# WKUP_CTRL_MMR0_CFG0 register map
Vendor: Texas Instruments
Registers are 32-bit, read-write, reset 0x0 unless marked. A register's access mark holds for its fields unless they carry their own. Offsets are as the file gives them; [hi:lo] are bit positions; lines under a group give offsets from that group; {n}, {i} and the like mark numbered series.

## WKUP_CTRL_MMR0_CFG0 (part 7 of 11)
0x1A0A0 CFG0_TEMP_DIODE_TRIM_PROXY
  [13:0] TEMP_DIODE_TRIM_TRIM_PROXY — Sets the diode non-ideality factor (n), starting from 100th place decimal and going down
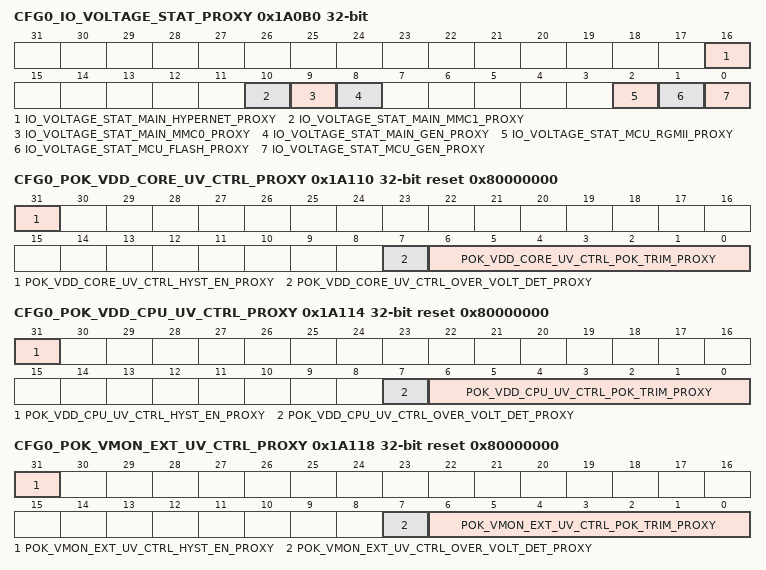
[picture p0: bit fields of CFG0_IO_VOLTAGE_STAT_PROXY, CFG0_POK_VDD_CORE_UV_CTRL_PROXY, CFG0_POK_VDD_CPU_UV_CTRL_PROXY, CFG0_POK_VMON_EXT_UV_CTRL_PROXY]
0x1A0B0 CFG0_IO_VOLTAGE_STAT_PROXY ro
  [16] IO_VOLTAGE_STAT_MAIN_HYPERNET_PROXY — Indicates the voltage for the HYPERNET I/O group 0 - I/O group is set for 1.8V 1 - I/O group is set for 3.3V
  [10] IO_VOLTAGE_STAT_MAIN_MMC1_PROXY — Indicates the voltage for the MMC1 I/O group 0 - I/O group is set for 1.8V 1 - I/O group is set for 3.3V
  [9] IO_VOLTAGE_STAT_MAIN_MMC0_PROXY — Indicates the voltage for the MMC0 I/O group 0 - I/O group is set for 1.8V 1 - I/O group is set for 3.3V
  [8] IO_VOLTAGE_STAT_MAIN_GEN_PROXY — Indicates the voltage for the General I/O group 0 - I/O group is set for 1.8V 1 - I/O group is set for 3.3V
  [2] IO_VOLTAGE_STAT_MCU_RGMII_PROXY — Indicates the voltage for the MCU CPSW2G RGMII I/O group 0 - I/O group is set for 1.8V 1 - I/O group is set for 3.3V
  [1] IO_VOLTAGE_STAT_MCU_FLASH_PROXY — Indicates the voltage for the MCU Flash I/O group 0 - I/O group is set for 1.8V 1 - I/O group is set for 3.3V
  [0] IO_VOLTAGE_STAT_MCU_GEN_PROXY — Indicates the voltage for the MCU General I/O group 0 - I/O group is set for 1.8V 1 - I/O group is set for 3.3V
0x1A104 CFG0_MAIN_POR_TO_CTRL_PROXY
  [2:0] MAIN_POR_TO_CTRL_TIMEOUT_PER_PROXY — MAIN PORz hardware timeout period. During normal operation, the assertion of a MAIN Domain PORz generates a reset request interrupt to the DMSC. The DMSC then performs steps to properly isolate the MAIN Domain before the actual reset is performed. A hardware timeout mechanism is provided to ensure that the PORz gets propagated to the MAIN Domain in the event that a error prevents the DMSC from completing the reset isolation. Field values (others are reserved): 3'b000 - Immediate 3'b001 - 100 microsec 3'b010 - 200 microsec 3'b011 - 300 microsec 3'b100 - 400 microsec 3'b101 - 500 microsec
0x1A110 CFG0_POK_VDD_CORE_UV_CTRL_PROXY reset 0x80000000
  [31] POK_VDD_CORE_UV_CTRL_HYST_EN_PROXY — Enable POK hysteresis
  [7] POK_VDD_CORE_UV_CTRL_OVER_VOLT_DET_PROXY — Over / under voltage detection mode 0 - Under voltage detection 1 - Over voltage detection
  [6:0] POK_VDD_CORE_UV_CTRL_POK_TRIM_PROXY — POK trim bits. These bits are used to trim the comparator threshold voltage. See POK spec and efuse spec for details
0x1A114 CFG0_POK_VDD_CPU_UV_CTRL_PROXY reset 0x80000000
  [31] POK_VDD_CPU_UV_CTRL_HYST_EN_PROXY — Enable POK hysteresis
  [7] POK_VDD_CPU_UV_CTRL_OVER_VOLT_DET_PROXY — Over / under voltage detection mode 0 - Under voltage detection 1 - Over voltage detection
  [6:0] POK_VDD_CPU_UV_CTRL_POK_TRIM_PROXY — POK trim bits. These bits are used to trim the comparator threshold voltage. See POK spec and efuse spec for details
0x1A118 CFG0_POK_VMON_EXT_UV_CTRL_PROXY reset 0x80000000
  [31] POK_VMON_EXT_UV_CTRL_HYST_EN_PROXY — Enable POK hysteresis
  [7] POK_VMON_EXT_UV_CTRL_OVER_VOLT_DET_PROXY — Over / under voltage detection mode 0 - Under voltage detection 1 - Over voltage detection
  [6:0] POK_VMON_EXT_UV_CTRL_POK_TRIM_PROXY — POK trim bits. These bits are used to trim the comparator threshold voltage. See POK spec and efuse spec for details
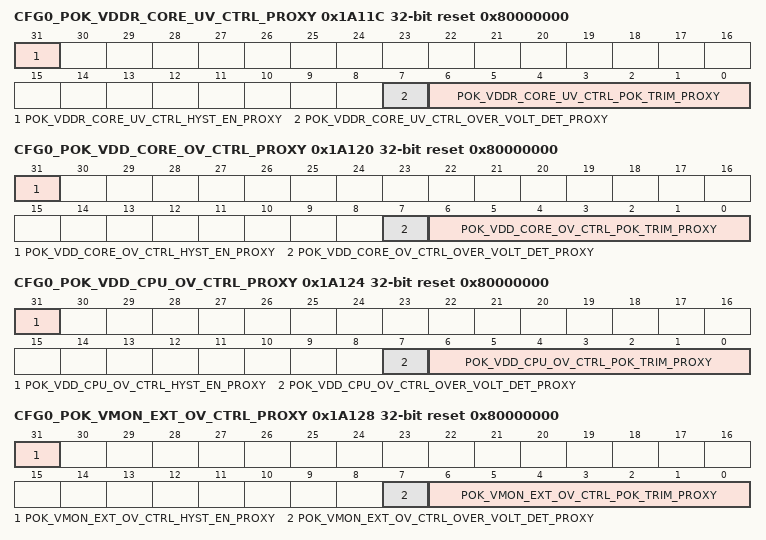
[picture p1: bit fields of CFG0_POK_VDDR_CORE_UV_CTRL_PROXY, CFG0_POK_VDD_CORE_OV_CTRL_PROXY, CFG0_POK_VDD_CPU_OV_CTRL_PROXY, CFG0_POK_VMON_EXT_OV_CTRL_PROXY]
0x1A11C CFG0_POK_VDDR_CORE_UV_CTRL_PROXY reset 0x80000000
  [31] POK_VDDR_CORE_UV_CTRL_HYST_EN_PROXY — Enable POK hysteresis
  [7] POK_VDDR_CORE_UV_CTRL_OVER_VOLT_DET_PROXY — Over / under voltage detection mode 0 - Under voltage detection 1 - Over voltage detection
  [6:0] POK_VDDR_CORE_UV_CTRL_POK_TRIM_PROXY — POK trim bits. These bits are used to trim the comparator threshold voltage. See POK spec and efuse spec for details
0x1A120 CFG0_POK_VDD_CORE_OV_CTRL_PROXY reset 0x80000000
  [31] POK_VDD_CORE_OV_CTRL_HYST_EN_PROXY — Enable POK hysteresis
  [7] POK_VDD_CORE_OV_CTRL_OVER_VOLT_DET_PROXY — Over / under voltage detection mode 0 - Under voltage detection 1 - Over voltage detection
  [6:0] POK_VDD_CORE_OV_CTRL_POK_TRIM_PROXY — POK trim bits. These bits are used to trim the comparator threshold voltage. See POK spec and efuse spec for details
0x1A124 CFG0_POK_VDD_CPU_OV_CTRL_PROXY reset 0x80000000
  [31] POK_VDD_CPU_OV_CTRL_HYST_EN_PROXY — Enable POK hysteresis
  [7] POK_VDD_CPU_OV_CTRL_OVER_VOLT_DET_PROXY — Over / under voltage detection mode 0 - Under voltage detection 1 - Over voltage detection
  [6:0] POK_VDD_CPU_OV_CTRL_POK_TRIM_PROXY — POK trim bits. These bits are used to trim the comparator threshold voltage. See POK spec and efuse spec for details
0x1A128 CFG0_POK_VMON_EXT_OV_CTRL_PROXY reset 0x80000000
  [31] POK_VMON_EXT_OV_CTRL_HYST_EN_PROXY — Enable POK hysteresis
  [7] POK_VMON_EXT_OV_CTRL_OVER_VOLT_DET_PROXY — Over / under voltage detection mode 0 - Under voltage detection 1 - Over voltage detection
  [6:0] POK_VMON_EXT_OV_CTRL_POK_TRIM_PROXY — POK trim bits. These bits are used to trim the comparator threshold voltage. See POK spec and efuse spec for details
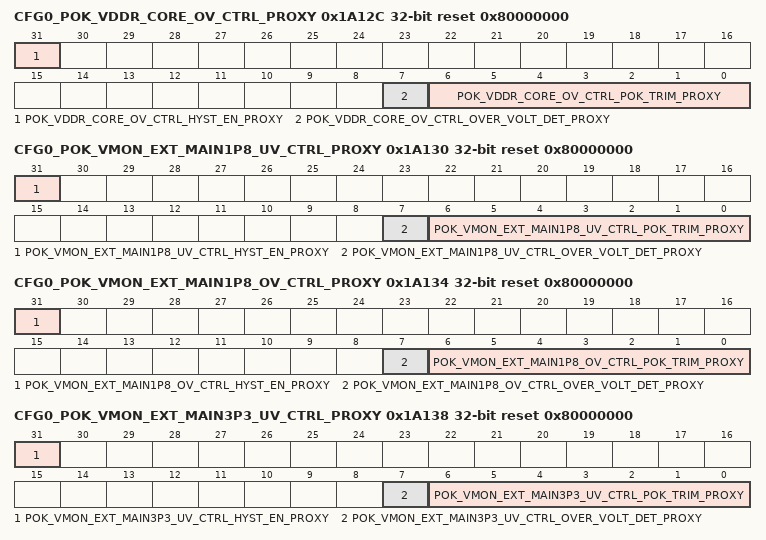
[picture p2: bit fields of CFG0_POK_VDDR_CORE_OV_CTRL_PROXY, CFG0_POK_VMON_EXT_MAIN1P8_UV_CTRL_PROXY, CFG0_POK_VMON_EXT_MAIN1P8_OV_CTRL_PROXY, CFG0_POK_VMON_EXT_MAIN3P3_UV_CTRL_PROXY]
0x1A12C CFG0_POK_VDDR_CORE_OV_CTRL_PROXY reset 0x80000000
  [31] POK_VDDR_CORE_OV_CTRL_HYST_EN_PROXY — Enable POK hysteresis
  [7] POK_VDDR_CORE_OV_CTRL_OVER_VOLT_DET_PROXY — Over / under voltage detection mode 0 - Under voltage detection 1 - Over voltage detection
  [6:0] POK_VDDR_CORE_OV_CTRL_POK_TRIM_PROXY — POK trim bits. These bits are used to trim the comparator threshold voltage. See POK spec and efuse spec for details
0x1A130 CFG0_POK_VMON_EXT_MAIN1P8_UV_CTRL_PROXY reset 0x80000000
  [31] POK_VMON_EXT_MAIN1P8_UV_CTRL_HYST_EN_PROXY — Enable POK hysteresis
  [7] POK_VMON_EXT_MAIN1P8_UV_CTRL_OVER_VOLT_DET_PROXY — Over / under voltage detection mode 0 - Under voltage detection 1 - Over voltage detection
  [6:0] POK_VMON_EXT_MAIN1P8_UV_CTRL_POK_TRIM_PROXY — POK trim bits. These bits are used to trim the comparator threshold voltage. See POK spec and efuse spec for details
0x1A134 CFG0_POK_VMON_EXT_MAIN1P8_OV_CTRL_PROXY reset 0x80000000
  [31] POK_VMON_EXT_MAIN1P8_OV_CTRL_HYST_EN_PROXY — Enable POK hysteresis
  [7] POK_VMON_EXT_MAIN1P8_OV_CTRL_OVER_VOLT_DET_PROXY — Over / under voltage detection mode 0 - Under voltage detection 1 - Over voltage detection
  [6:0] POK_VMON_EXT_MAIN1P8_OV_CTRL_POK_TRIM_PROXY — POK trim bits. These bits are used to trim the comparator threshold voltage. See POK spec and efuse spec for details
0x1A138 CFG0_POK_VMON_EXT_MAIN3P3_UV_CTRL_PROXY reset 0x80000000
  [31] POK_VMON_EXT_MAIN3P3_UV_CTRL_HYST_EN_PROXY — Enable POK hysteresis
  [7] POK_VMON_EXT_MAIN3P3_UV_CTRL_OVER_VOLT_DET_PROXY — Over / under voltage detection mode 0 - Under voltage detection 1 - Over voltage detection
  [6:0] POK_VMON_EXT_MAIN3P3_UV_CTRL_POK_TRIM_PROXY — POK trim bits. These bits are used to trim the comparator threshold voltage. See POK spec and efuse spec for details
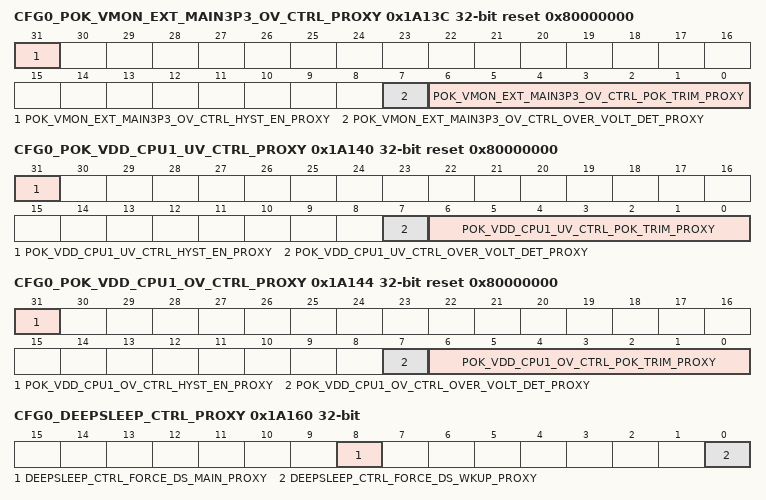
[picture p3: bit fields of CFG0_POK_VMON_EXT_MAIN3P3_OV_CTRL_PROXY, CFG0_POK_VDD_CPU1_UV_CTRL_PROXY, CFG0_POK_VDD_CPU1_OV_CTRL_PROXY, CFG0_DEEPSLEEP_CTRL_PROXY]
0x1A13C CFG0_POK_VMON_EXT_MAIN3P3_OV_CTRL_PROXY reset 0x80000000
  [31] POK_VMON_EXT_MAIN3P3_OV_CTRL_HYST_EN_PROXY — Enable POK hysteresis
  [7] POK_VMON_EXT_MAIN3P3_OV_CTRL_OVER_VOLT_DET_PROXY — Over / under voltage detection mode 0 - Under voltage detection 1 - Over voltage detection
  [6:0] POK_VMON_EXT_MAIN3P3_OV_CTRL_POK_TRIM_PROXY — POK trim bits. These bits are used to trim the comparator threshold voltage. See POK spec and efuse spec for details
0x1A140 CFG0_POK_VDD_CPU1_UV_CTRL_PROXY reset 0x80000000
  [31] POK_VDD_CPU1_UV_CTRL_HYST_EN_PROXY — Enable POK hysteresis
  [7] POK_VDD_CPU1_UV_CTRL_OVER_VOLT_DET_PROXY — Over / under voltage detection mode 0 - Under voltage detection 1 - Over voltage detection
  [6:0] POK_VDD_CPU1_UV_CTRL_POK_TRIM_PROXY — POK trim bits. These bits are used to trim the comparator threshold voltage. See POK spec and efuse spec for details
0x1A144 CFG0_POK_VDD_CPU1_OV_CTRL_PROXY reset 0x80000000
  [31] POK_VDD_CPU1_OV_CTRL_HYST_EN_PROXY — Enable POK hysteresis
  [7] POK_VDD_CPU1_OV_CTRL_OVER_VOLT_DET_PROXY — Over / under voltage detection mode 0 - Under voltage detection 1 - Over voltage detection
  [6:0] POK_VDD_CPU1_OV_CTRL_POK_TRIM_PROXY — POK trim bits. These bits are used to trim the comparator threshold voltage. See POK spec and efuse spec for details
{0x1A150+4i} CFG0_POK_RSV{i}_PROXY access not given (i=0..3)
0x1A160 CFG0_DEEPSLEEP_CTRL_PROXY
  [8] DEEPSLEEP_CTRL_FORCE_DS_MAIN_PROXY — Force all MAIN IOs into deepsleep mode when set
  [0] DEEPSLEEP_CTRL_FORCE_DS_WKUP_PROXY — Force all WKUP IOs into deepsleep mode when set
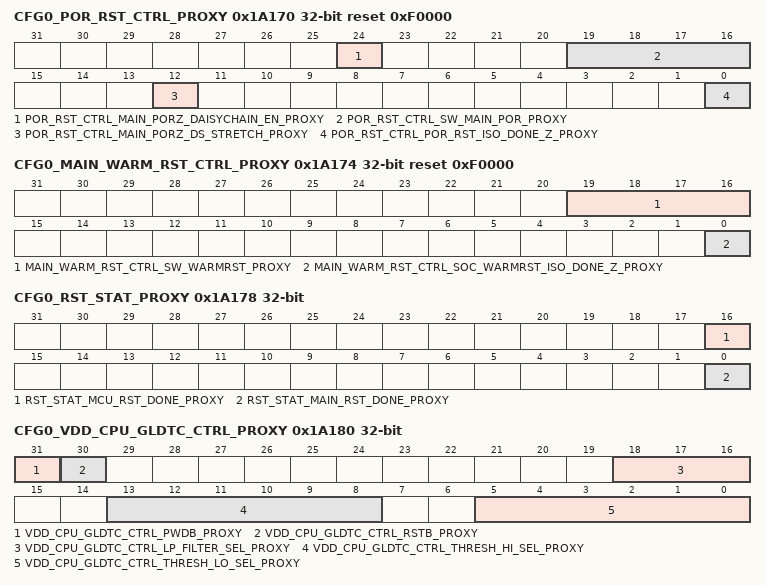
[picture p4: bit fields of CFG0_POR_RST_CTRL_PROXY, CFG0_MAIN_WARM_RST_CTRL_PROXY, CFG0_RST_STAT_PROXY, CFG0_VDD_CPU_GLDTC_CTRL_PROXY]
0x1A170 CFG0_POR_RST_CTRL_PROXY reset 0xF0000
  [24] POR_RST_CTRL_MAIN_PORZ_DAISYCHAIN_EN_PROXY — MAIN PORz daisy-chain event enable. Determines if MAIN PORz reset events affect daisy-chain wakeup 0 - DeepSleep MAIN PORz event is not part of daisy-chain 1 - DeepSleep MAIN PORz event is combined w/ other daisy chain events.
  [19:16] POR_RST_CTRL_SW_MAIN_POR_PROXY — Main Domain software power-on reset. When set to 4'b0110, a power-on is issued to the MAIN voltage domain. (Bits will reset to 4'b1111 on reset of the Main Domain)
  [12] POR_RST_CTRL_MAIN_PORZ_DS_STRETCH_PROXY — DeepSleep mode MAIN PORz stretch. 0 - No stretching 1 - Stretch the Main PORz event captured during DeepSleep mode
  [0] POR_RST_CTRL_POR_RST_ISO_DONE_Z_PROXY — Reset isolation completion (active low). This bit should be cleared only after reset isolation of the MAIN domain is complete. 0 - POR reset propagates to MAIN domain 1 - POR reset blocked from MAIN domain
0x1A174 CFG0_MAIN_WARM_RST_CTRL_PROXY reset 0xF0000
  [19:16] MAIN_WARM_RST_CTRL_SW_WARMRST_PROXY — Main Domain software warm reset. When set to 4'b0110, a warm reset is issued to the MAIN voltage domain. (Bits will reset to 4'b1111 on reset of the Main Domain)
  [0] MAIN_WARM_RST_CTRL_SOC_WARMRST_ISO_DONE_Z_PROXY — Reset isolation completion (active low). This bit should be cleared only after reset isolation of the MAIN domain is complete. 0 - Warm reset propagates to MAIN domain 1 - Warm reset blocked from MAIN domain
0x1A178 CFG0_RST_STAT_PROXY ro
  [16] RST_STAT_MCU_RST_DONE_PROXY — Indicates MCU domain reset status. 0 - MCU domain is in reset 1 - MCU domain reset is complete
  [0] RST_STAT_MAIN_RST_DONE_PROXY — Indicates MAIN domain Warm reset status. 0 - MAIN domain is in Warm reset 1 - MAIN domain Warm reset is complete
0x1A17C CFG0_MCU_WARM_RST_CTRL_PROXY reset 0xF0000
  [19:16] MCU_WARM_RST_CTRL_SW_WARMRST_PROXY — Chip software warm reset. When set to 4'b0110, a warm reset is issued to the device (all voltage domains). (Bits will reset to 4'b1111 on reset completion.)
0x1A180 CFG0_VDD_CPU_GLDTC_CTRL_PROXY
  [31] VDD_CPU_GLDTC_CTRL_PWDB_PROXY — Power down - active low. 0 - Disable all functions 1 - Enable glitch detectors
  [30] VDD_CPU_GLDTC_CTRL_RSTB_PROXY — Reset - active low. To ensure proper operation, rstb must be not be de-asserted for at least 100 ns after power-up (pwdb de-asserted). Additionally, rstb must be toggled low at least 200 ns after any change in threshold or low-pass filter settings to prevent abnormal trigger events. 0 - Reset glitch detector flags 1 - Glitch detection flags are enabled
  [18:16] VDD_CPU_GLDTC_CTRL_LP_FILTER_SEL_PROXY — Selects the glitch detect low-pass filter bandwidth Field values (others are reserved): 3'b000 - 150 kHz 3'b001 - 125 kHz 3'b010 - 100 kHz 3'b011 - 80 kHz 3'b100 - 60 kHz 3'b101 - 45 kHz 3'b110 - 30 kHz 3'b111 - 15 kHz
  [13:8] VDD_CPU_GLDTC_CTRL_THRESH_HI_SEL_PROXY — Selects the high voltage glitch threshold as a percentage of the monitored voltage Field values (others are reserved): 6'b000000 - 93.5% of VDD 6'b000001 - 94.0% of VDD 6'b000010 - 94.5% of VDD 6'b000011 - 95.0% of VDD 6'b000100 - 95.5% of VDD 6'b000101 - 96.0% of VDD 6'b000110 - 96.5% of VDD 6'b000111 - 97.0% of VDD 6'b001000 - 97.5% of VDD 6'b001001 - 98.0% of VDD 6'b001010 - 98.5% of VDD 6'b001011 - 99.0% of VDD 6'b001100 - 99.5% of VDD 6'b001101 - 100.0% of VDD 6'b001110 - 100.5% of VDD 6'b001111 - 101.0% of VDD 6'b010000 - 101.5% of VDD 6'b010001 - 102.0% of VDD 6'b010010 - 102.5% of VDD 6'b010011 - 103.0% of VDD 6'b010100 - 103.5% of VDD 6'b010101 - 104.0% of VDD 6'b010110 - 104.5% of VDD 6'b010111 - 105.0% of VDD 6'b011000 - 105.5% of VDD 6'b011001 - 106.0% of VDD 6'b011010 - 106.5% of VDD 6'b011011 - 107.0% of VDD 6'b011100 - 107.5% of VDD 6'b011101 - 108.0% of VDD 6'b011110 - 108.5% of VDD 6'b011111 - 109.0% of VDD 6'b100000 - 109.5% of VDD 6'b100001 - 110.0% of VDD 6'b100010 - 111.0% of VDD 6'b100011 - 112.0% of VDD 6'b100100 - 113.0% of VDD 6'b100101 - 114.0% of VDD 6'b100110 - 115.0% of VDD 6'b100111 - 116.0% of VDD 6'b101000 - 117.0% of VDD 6'b101001 - 118.0% of VDD 6'b101010 - 119.0% of VDD 6'b101011 - 120.0% of VDD 6'b101100 - 121.0% of VDD 6'b101101 - 122.0% of VDD 6'b101110 - 123.0% of VDD 6'b101111 - 124.0% of VDD 6'b110000 - 125.0% of VDD 6'b110001 - 126.0% of VDD 6'b110010 - 127.0% of VDD 6'b110011 - 128.0% of VDD 6'b110100 - 129.0% of VDD 6'b110101 - 130.0% of VDD 6'b110110 - 131.0% of VDD 6'b110111 - 132.0% of VDD 6'b111000 - 133.0% of VDD 6'b111001 - 134.0% of VDD 6'b111010 - 135.0% of VDD 6'b111011 - 136.0% of VDD 6'b111100 - 137.0% of VDD 6'b111101 - 138.0% of VDD 6'b111110 - 139.0% of VDD 6'b111111 - 140.0% of VDD
  [5:0] VDD_CPU_GLDTC_CTRL_THRESH_LO_SEL_PROXY — Selects the low voltage glitch threshold as a percentage of the monitored voltage Field values (others are reserved): 6'b000000 - 106.5% of VDD 6'b000001 - 106.0% of VDD 6'b000010 - 105.5% of VDD 6'b000011 - 105.0% of VDD 6'b000100 - 104.5% of VDD 6'b000101 - 104.0% of VDD 6'b000110 - 103.5% of VDD 6'b000111 - 103.0% of VDD 6'b001000 - 102.5% of VDD 6'b001001 - 102.0% of VDD 6'b001010 - 101.5% of VDD 6'b001011 - 101.0% of VDD 6'b001100 - 100.5% of VDD 6'b001101 - 100.0% of VDD 6'b001110 - 99.5% of VDD 6'b001111 - 99.0% of VDD 6'b010000 - 98.5% of VDD 6'b010001 - 98.0% of VDD 6'b010010 - 97.5% of VDD 6'b010011 - 97.0% of VDD 6'b010100 - 96.5% of VDD 6'b010101 - 96.0% of VDD 6'b010110 - 95.5% of VDD 6'b010111 - 95.0% of VDD 6'b011000 - 94.5% of VDD 6'b011001 - 94.0% of VDD 6'b011010 - 93.5% of VDD 6'b011011 - 93.0% of VDD 6'b011100 - 92.5% of VDD 6'b011101 - 92.0% of VDD 6'b011110 - 91.5% of VDD 6'b011111 - 91.0% of VDD 6'b100000 - 90.5% of VDD 6'b100001 - 90.0% of VDD 6'b100010 - 89.0% of VDD 6'b100011 - 88.0% of VDD 6'b100100 - 87.0% of VDD 6'b100101 - 86.0% of VDD 6'b100110 - 85.0% of VDD 6'b100111 - 84.0% of VDD 6'b101000 - 83.0% of VDD 6'b101001 - 82.0% of VDD 6'b101010 - 81.0% of VDD 6'b101011 - 80.0% of VDD 6'b101100 - 79.0% of VDD 6'b101101 - 78.0% of VDD 6'b101110 - 77.0% of VDD 6'b101111 - 76.0% of VDD 6'b110000 - 75.0% of VDD 6'b110001 - 74.0% of VDD 6'b110010 - 73.0% of VDD 6'b110011 - 72.0% of VDD 6'b110100 - 71.0% of VDD 6'b110101 - 70.0% of VDD 6'b110110 - 69.0% of VDD 6'b110111 - 68.0% of VDD 6'b111000 - 67.0% of VDD 6'b111001 - 66.0% of VDD 6'b111010 - 65.0% of VDD 6'b111011 - 64.0% of VDD 6'b111100 - 63.0% of VDD 6'b111101 - 62.0% of VDD 6'b111110 - 61.0% of VDD 6'b111111 - 60.0% of VDD
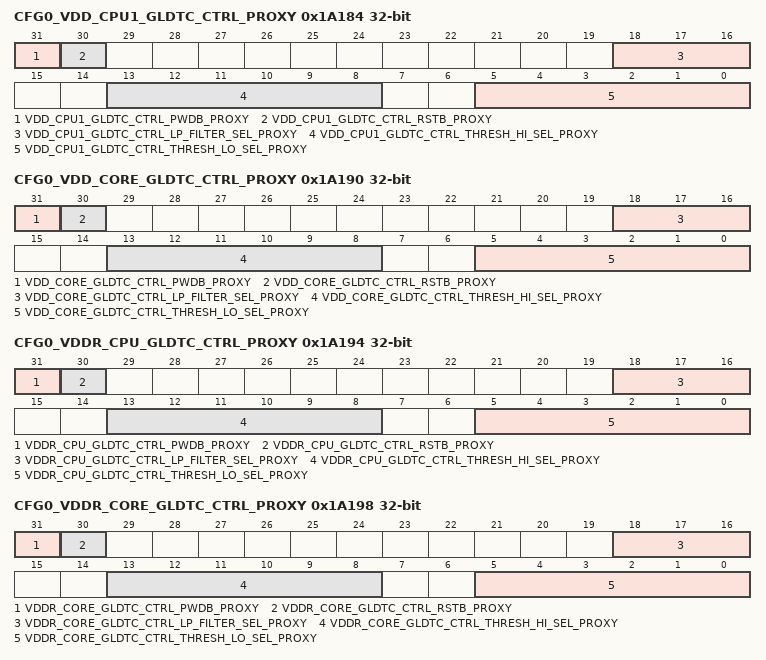
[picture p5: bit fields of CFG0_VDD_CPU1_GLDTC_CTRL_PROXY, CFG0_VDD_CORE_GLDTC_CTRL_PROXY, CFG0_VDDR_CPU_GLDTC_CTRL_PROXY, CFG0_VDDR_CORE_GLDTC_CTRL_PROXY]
0x1A184 CFG0_VDD_CPU1_GLDTC_CTRL_PROXY
  [31] VDD_CPU1_GLDTC_CTRL_PWDB_PROXY — Power down - active low. 0 - Disable all functions 1 - Enable glitch detectors
  [30] VDD_CPU1_GLDTC_CTRL_RSTB_PROXY — Reset - active low. To ensure proper operation, rstb must be not be de-asserted for at least 100 ns after power-up (pwdb de-asserted). Additionally, rstb must be toggled low at least 200 ns after any change in threshold or low-pass filter settings to prevent abnormal trigger events. 0 - Reset glitch detector flags 1 - Glitch detection flags are enabled
  [18:16] VDD_CPU1_GLDTC_CTRL_LP_FILTER_SEL_PROXY — Selects the glitch detect low-pass filter bandwidth Field values (others are reserved): 3'b000 - 150 kHz 3'b001 - 125 kHz 3'b010 - 100 kHz 3'b011 - 80 kHz 3'b100 - 60 kHz 3'b101 - 45 kHz 3'b110 - 30 kHz 3'b111 - 15 kHz
  [13:8] VDD_CPU1_GLDTC_CTRL_THRESH_HI_SEL_PROXY — Selects the high voltage glitch threshold as a percentage of the monitored voltage Field values (others are reserved): 6'b000000 - 93.5% of VDD 6'b000001 - 94.0% of VDD 6'b000010 - 94.5% of VDD 6'b000011 - 95.0% of VDD 6'b000100 - 95.5% of VDD 6'b000101 - 96.0% of VDD 6'b000110 - 96.5% of VDD 6'b000111 - 97.0% of VDD 6'b001000 - 97.5% of VDD 6'b001001 - 98.0% of VDD 6'b001010 - 98.5% of VDD 6'b001011 - 99.0% of VDD 6'b001100 - 99.5% of VDD 6'b001101 - 100.0% of VDD 6'b001110 - 100.5% of VDD 6'b001111 - 101.0% of VDD 6'b010000 - 101.5% of VDD 6'b010001 - 102.0% of VDD 6'b010010 - 102.5% of VDD 6'b010011 - 103.0% of VDD 6'b010100 - 103.5% of VDD 6'b010101 - 104.0% of VDD 6'b010110 - 104.5% of VDD 6'b010111 - 105.0% of VDD 6'b011000 - 105.5% of VDD 6'b011001 - 106.0% of VDD 6'b011010 - 106.5% of VDD 6'b011011 - 107.0% of VDD 6'b011100 - 107.5% of VDD 6'b011101 - 108.0% of VDD 6'b011110 - 108.5% of VDD 6'b011111 - 109.0% of VDD 6'b100000 - 109.5% of VDD 6'b100001 - 110.0% of VDD 6'b100010 - 111.0% of VDD 6'b100011 - 112.0% of VDD 6'b100100 - 113.0% of VDD 6'b100101 - 114.0% of VDD 6'b100110 - 115.0% of VDD 6'b100111 - 116.0% of VDD 6'b101000 - 117.0% of VDD 6'b101001 - 118.0% of VDD 6'b101010 - 119.0% of VDD 6'b101011 - 120.0% of VDD 6'b101100 - 121.0% of VDD 6'b101101 - 122.0% of VDD 6'b101110 - 123.0% of VDD 6'b101111 - 124.0% of VDD 6'b110000 - 125.0% of VDD 6'b110001 - 126.0% of VDD 6'b110010 - 127.0% of VDD 6'b110011 - 128.0% of VDD 6'b110100 - 129.0% of VDD 6'b110101 - 130.0% of VDD 6'b110110 - 131.0% of VDD 6'b110111 - 132.0% of VDD 6'b111000 - 133.0% of VDD 6'b111001 - 134.0% of VDD 6'b111010 - 135.0% of VDD 6'b111011 - 136.0% of VDD 6'b111100 - 137.0% of VDD 6'b111101 - 138.0% of VDD 6'b111110 - 139.0% of VDD 6'b111111 - 140.0% of VDD
  [5:0] VDD_CPU1_GLDTC_CTRL_THRESH_LO_SEL_PROXY — Selects the low voltage glitch threshold as a percentage of the monitored voltage Field values (others are reserved): 6'b000000 - 106.5% of VDD 6'b000001 - 106.0% of VDD 6'b000010 - 105.5% of VDD 6'b000011 - 105.0% of VDD 6'b000100 - 104.5% of VDD 6'b000101 - 104.0% of VDD 6'b000110 - 103.5% of VDD 6'b000111 - 103.0% of VDD 6'b001000 - 102.5% of VDD 6'b001001 - 102.0% of VDD 6'b001010 - 101.5% of VDD 6'b001011 - 101.0% of VDD 6'b001100 - 100.5% of VDD 6'b001101 - 100.0% of VDD 6'b001110 - 99.5% of VDD 6'b001111 - 99.0% of VDD 6'b010000 - 98.5% of VDD 6'b010001 - 98.0% of VDD 6'b010010 - 97.5% of VDD 6'b010011 - 97.0% of VDD 6'b010100 - 96.5% of VDD 6'b010101 - 96.0% of VDD 6'b010110 - 95.5% of VDD 6'b010111 - 95.0% of VDD 6'b011000 - 94.5% of VDD 6'b011001 - 94.0% of VDD 6'b011010 - 93.5% of VDD 6'b011011 - 93.0% of VDD 6'b011100 - 92.5% of VDD 6'b011101 - 92.0% of VDD 6'b011110 - 91.5% of VDD 6'b011111 - 91.0% of VDD 6'b100000 - 90.5% of VDD 6'b100001 - 90.0% of VDD 6'b100010 - 89.0% of VDD 6'b100011 - 88.0% of VDD 6'b100100 - 87.0% of VDD 6'b100101 - 86.0% of VDD 6'b100110 - 85.0% of VDD 6'b100111 - 84.0% of VDD 6'b101000 - 83.0% of VDD 6'b101001 - 82.0% of VDD 6'b101010 - 81.0% of VDD 6'b101011 - 80.0% of VDD 6'b101100 - 79.0% of VDD 6'b101101 - 78.0% of VDD 6'b101110 - 77.0% of VDD 6'b101111 - 76.0% of VDD 6'b110000 - 75.0% of VDD 6'b110001 - 74.0% of VDD 6'b110010 - 73.0% of VDD 6'b110011 - 72.0% of VDD 6'b110100 - 71.0% of VDD 6'b110101 - 70.0% of VDD 6'b110110 - 69.0% of VDD 6'b110111 - 68.0% of VDD 6'b111000 - 67.0% of VDD 6'b111001 - 66.0% of VDD 6'b111010 - 65.0% of VDD 6'b111011 - 64.0% of VDD 6'b111100 - 63.0% of VDD 6'b111101 - 62.0% of VDD 6'b111110 - 61.0% of VDD 6'b111111 - 60.0% of VDD
0x1A190 CFG0_VDD_CORE_GLDTC_CTRL_PROXY
  [31] VDD_CORE_GLDTC_CTRL_PWDB_PROXY — Power down - active low. 0 - Disable all functions 1 - Enable glitch detectors
  [30] VDD_CORE_GLDTC_CTRL_RSTB_PROXY — Reset - active low. To ensure proper operation, rstb must be not be de-asserted for at least 100 ns after power-up (pwdb de-asserted). Additionally, rstb must be toggled low at least 200 ns after any change in threshold or low-pass filter settings to prevent abnormal trigger events. 0 - Reset glitch detector flags 1 - Glitch detection flags are enabled
  [18:16] VDD_CORE_GLDTC_CTRL_LP_FILTER_SEL_PROXY — Selects the glitch detect low-pass filter bandwidth Field values (others are reserved): 3'b000 - 150 kHz 3'b001 - 125 kHz 3'b010 - 100 kHz 3'b011 - 80 kHz 3'b100 - 60 kHz 3'b101 - 45 kHz 3'b110 - 30 kHz 3'b111 - 15 kHz
  [13:8] VDD_CORE_GLDTC_CTRL_THRESH_HI_SEL_PROXY — Selects the high voltage glitch threshold as a percentage of the monitored voltage Field values (others are reserved): 6'b000000 - 93.5% of VDD 6'b000001 - 94.0% of VDD 6'b000010 - 94.5% of VDD 6'b000011 - 95.0% of VDD 6'b000100 - 95.5% of VDD 6'b000101 - 96.0% of VDD 6'b000110 - 96.5% of VDD 6'b000111 - 97.0% of VDD 6'b001000 - 97.5% of VDD 6'b001001 - 98.0% of VDD 6'b001010 - 98.5% of VDD 6'b001011 - 99.0% of VDD 6'b001100 - 99.5% of VDD 6'b001101 - 100.0% of VDD 6'b001110 - 100.5% of VDD 6'b001111 - 101.0% of VDD 6'b010000 - 101.5% of VDD 6'b010001 - 102.0% of VDD 6'b010010 - 102.5% of VDD 6'b010011 - 103.0% of VDD 6'b010100 - 103.5% of VDD 6'b010101 - 104.0% of VDD 6'b010110 - 104.5% of VDD 6'b010111 - 105.0% of VDD 6'b011000 - 105.5% of VDD 6'b011001 - 106.0% of VDD 6'b011010 - 106.5% of VDD 6'b011011 - 107.0% of VDD 6'b011100 - 107.5% of VDD 6'b011101 - 108.0% of VDD 6'b011110 - 108.5% of VDD 6'b011111 - 109.0% of VDD 6'b100000 - 109.5% of VDD 6'b100001 - 110.0% of VDD 6'b100010 - 111.0% of VDD 6'b100011 - 112.0% of VDD 6'b100100 - 113.0% of VDD 6'b100101 - 114.0% of VDD 6'b100110 - 115.0% of VDD 6'b100111 - 116.0% of VDD 6'b101000 - 117.0% of VDD 6'b101001 - 118.0% of VDD 6'b101010 - 119.0% of VDD 6'b101011 - 120.0% of VDD 6'b101100 - 121.0% of VDD 6'b101101 - 122.0% of VDD 6'b101110 - 123.0% of VDD 6'b101111 - 124.0% of VDD 6'b110000 - 125.0% of VDD 6'b110001 - 126.0% of VDD 6'b110010 - 127.0% of VDD 6'b110011 - 128.0% of VDD 6'b110100 - 129.0% of VDD 6'b110101 - 130.0% of VDD 6'b110110 - 131.0% of VDD 6'b110111 - 132.0% of VDD 6'b111000 - 133.0% of VDD 6'b111001 - 134.0% of VDD 6'b111010 - 135.0% of VDD 6'b111011 - 136.0% of VDD 6'b111100 - 137.0% of VDD 6'b111101 - 138.0% of VDD 6'b111110 - 139.0% of VDD 6'b111111 - 140.0% of VDD
  [5:0] VDD_CORE_GLDTC_CTRL_THRESH_LO_SEL_PROXY — Selects the low voltage glitch threshold as a percentage of the monitored voltage Field values (others are reserved): 6'b000000 - 106.5% of VDD 6'b000001 - 106.0% of VDD 6'b000010 - 105.5% of VDD 6'b000011 - 105.0% of VDD 6'b000100 - 104.5% of VDD 6'b000101 - 104.0% of VDD 6'b000110 - 103.5% of VDD 6'b000111 - 103.0% of VDD 6'b001000 - 102.5% of VDD 6'b001001 - 102.0% of VDD 6'b001010 - 101.5% of VDD 6'b001011 - 101.0% of VDD 6'b001100 - 100.5% of VDD 6'b001101 - 100.0% of VDD 6'b001110 - 99.5% of VDD 6'b001111 - 99.0% of VDD 6'b010000 - 98.5% of VDD 6'b010001 - 98.0% of VDD 6'b010010 - 97.5% of VDD 6'b010011 - 97.0% of VDD 6'b010100 - 96.5% of VDD 6'b010101 - 96.0% of VDD 6'b010110 - 95.5% of VDD 6'b010111 - 95.0% of VDD 6'b011000 - 94.5% of VDD 6'b011001 - 94.0% of VDD 6'b011010 - 93.5% of VDD 6'b011011 - 93.0% of VDD 6'b011100 - 92.5% of VDD 6'b011101 - 92.0% of VDD 6'b011110 - 91.5% of VDD 6'b011111 - 91.0% of VDD 6'b100000 - 90.5% of VDD 6'b100001 - 90.0% of VDD 6'b100010 - 89.0% of VDD 6'b100011 - 88.0% of VDD 6'b100100 - 87.0% of VDD 6'b100101 - 86.0% of VDD 6'b100110 - 85.0% of VDD 6'b100111 - 84.0% of VDD 6'b101000 - 83.0% of VDD 6'b101001 - 82.0% of VDD 6'b101010 - 81.0% of VDD 6'b101011 - 80.0% of VDD 6'b101100 - 79.0% of VDD 6'b101101 - 78.0% of VDD 6'b101110 - 77.0% of VDD 6'b101111 - 76.0% of VDD 6'b110000 - 75.0% of VDD 6'b110001 - 74.0% of VDD 6'b110010 - 73.0% of VDD 6'b110011 - 72.0% of VDD 6'b110100 - 71.0% of VDD 6'b110101 - 70.0% of VDD 6'b110110 - 69.0% of VDD 6'b110111 - 68.0% of VDD 6'b111000 - 67.0% of VDD 6'b111001 - 66.0% of VDD 6'b111010 - 65.0% of VDD 6'b111011 - 64.0% of VDD 6'b111100 - 63.0% of VDD 6'b111101 - 62.0% of VDD 6'b111110 - 61.0% of VDD 6'b111111 - 60.0% of VDD
0x1A194 CFG0_VDDR_CPU_GLDTC_CTRL_PROXY
  [31] VDDR_CPU_GLDTC_CTRL_PWDB_PROXY — Power down - active low. 0 - Disable all functions 1 - Enable glitch detectors
  [30] VDDR_CPU_GLDTC_CTRL_RSTB_PROXY — Reset - active low. To ensure proper operation, rstb must be not be de-asserted for at least 100 ns after power-up (pwdb de-asserted). Additionally, rstb must be toggled low at least 200 ns after any change in threshold or low-pass filter settings to prevent abnormal trigger events. 0 - Reset glitch detector flags 1 - Glitch detection flags are enabled
  [18:16] VDDR_CPU_GLDTC_CTRL_LP_FILTER_SEL_PROXY — Selects the glitch detect low-pass filter bandwidth Field values (others are reserved): 3'b000 - 150 kHz 3'b001 - 125 kHz 3'b010 - 100 kHz 3'b011 - 80 kHz 3'b100 - 60 kHz 3'b101 - 45 kHz 3'b110 - 30 kHz 3'b111 - 15 kHz
  [13:8] VDDR_CPU_GLDTC_CTRL_THRESH_HI_SEL_PROXY — Selects the high voltage glitch threshold as a percentage of the monitored voltage Field values (others are reserved): 6'b000000 - 93.5% of VDD 6'b000001 - 94.0% of VDD 6'b000010 - 94.5% of VDD 6'b000011 - 95.0% of VDD 6'b000100 - 95.5% of VDD 6'b000101 - 96.0% of VDD 6'b000110 - 96.5% of VDD 6'b000111 - 97.0% of VDD 6'b001000 - 97.5% of VDD 6'b001001 - 98.0% of VDD 6'b001010 - 98.5% of VDD 6'b001011 - 99.0% of VDD 6'b001100 - 99.5% of VDD 6'b001101 - 100.0% of VDD 6'b001110 - 100.5% of VDD 6'b001111 - 101.0% of VDD 6'b010000 - 101.5% of VDD 6'b010001 - 102.0% of VDD 6'b010010 - 102.5% of VDD 6'b010011 - 103.0% of VDD 6'b010100 - 103.5% of VDD 6'b010101 - 104.0% of VDD 6'b010110 - 104.5% of VDD 6'b010111 - 105.0% of VDD 6'b011000 - 105.5% of VDD 6'b011001 - 106.0% of VDD 6'b011010 - 106.5% of VDD 6'b011011 - 107.0% of VDD 6'b011100 - 107.5% of VDD 6'b011101 - 108.0% of VDD 6'b011110 - 108.5% of VDD 6'b011111 - 109.0% of VDD 6'b100000 - 109.5% of VDD 6'b100001 - 110.0% of VDD 6'b100010 - 111.0% of VDD 6'b100011 - 112.0% of VDD 6'b100100 - 113.0% of VDD 6'b100101 - 114.0% of VDD 6'b100110 - 115.0% of VDD 6'b100111 - 116.0% of VDD 6'b101000 - 117.0% of VDD 6'b101001 - 118.0% of VDD 6'b101010 - 119.0% of VDD 6'b101011 - 120.0% of VDD 6'b101100 - 121.0% of VDD 6'b101101 - 122.0% of VDD 6'b101110 - 123.0% of VDD 6'b101111 - 124.0% of VDD 6'b110000 - 125.0% of VDD 6'b110001 - 126.0% of VDD 6'b110010 - 127.0% of VDD 6'b110011 - 128.0% of VDD 6'b110100 - 129.0% of VDD 6'b110101 - 130.0% of VDD 6'b110110 - 131.0% of VDD 6'b110111 - 132.0% of VDD 6'b111000 - 133.0% of VDD 6'b111001 - 134.0% of VDD 6'b111010 - 135.0% of VDD 6'b111011 - 136.0% of VDD 6'b111100 - 137.0% of VDD 6'b111101 - 138.0% of VDD 6'b111110 - 139.0% of VDD 6'b111111 - 140.0% of VDD
  [5:0] VDDR_CPU_GLDTC_CTRL_THRESH_LO_SEL_PROXY — Selects the low voltage glitch threshold as a percentage of the monitored voltage Field values (others are reserved): 6'b000000 - 106.5% of VDD 6'b000001 - 106.0% of VDD 6'b000010 - 105.5% of VDD 6'b000011 - 105.0% of VDD 6'b000100 - 104.5% of VDD 6'b000101 - 104.0% of VDD 6'b000110 - 103.5% of VDD 6'b000111 - 103.0% of VDD 6'b001000 - 102.5% of VDD 6'b001001 - 102.0% of VDD 6'b001010 - 101.5% of VDD 6'b001011 - 101.0% of VDD 6'b001100 - 100.5% of VDD 6'b001101 - 100.0% of VDD 6'b001110 - 99.5% of VDD 6'b001111 - 99.0% of VDD 6'b010000 - 98.5% of VDD 6'b010001 - 98.0% of VDD 6'b010010 - 97.5% of VDD 6'b010011 - 97.0% of VDD 6'b010100 - 96.5% of VDD 6'b010101 - 96.0% of VDD 6'b010110 - 95.5% of VDD 6'b010111 - 95.0% of VDD 6'b011000 - 94.5% of VDD 6'b011001 - 94.0% of VDD 6'b011010 - 93.5% of VDD 6'b011011 - 93.0% of VDD 6'b011100 - 92.5% of VDD 6'b011101 - 92.0% of VDD 6'b011110 - 91.5% of VDD 6'b011111 - 91.0% of VDD 6'b100000 - 90.5% of VDD 6'b100001 - 90.0% of VDD 6'b100010 - 89.0% of VDD 6'b100011 - 88.0% of VDD 6'b100100 - 87.0% of VDD 6'b100101 - 86.0% of VDD 6'b100110 - 85.0% of VDD 6'b100111 - 84.0% of VDD 6'b101000 - 83.0% of VDD 6'b101001 - 82.0% of VDD 6'b101010 - 81.0% of VDD 6'b101011 - 80.0% of VDD 6'b101100 - 79.0% of VDD 6'b101101 - 78.0% of VDD 6'b101110 - 77.0% of VDD 6'b101111 - 76.0% of VDD 6'b110000 - 75.0% of VDD 6'b110001 - 74.0% of VDD 6'b110010 - 73.0% of VDD 6'b110011 - 72.0% of VDD 6'b110100 - 71.0% of VDD 6'b110101 - 70.0% of VDD 6'b110110 - 69.0% of VDD 6'b110111 - 68.0% of VDD 6'b111000 - 67.0% of VDD 6'b111001 - 66.0% of VDD 6'b111010 - 65.0% of VDD 6'b111011 - 64.0% of VDD 6'b111100 - 63.0% of VDD 6'b111101 - 62.0% of VDD 6'b111110 - 61.0% of VDD 6'b111111 - 60.0% of VDD
0x1A198 CFG0_VDDR_CORE_GLDTC_CTRL_PROXY
  [31] VDDR_CORE_GLDTC_CTRL_PWDB_PROXY — Power down - active low. 0 - Disable all functions 1 - Enable glitch detectors
  [30] VDDR_CORE_GLDTC_CTRL_RSTB_PROXY — Reset - active low. To ensure proper operation, rstb must be not be de-asserted for at least 100 ns after power-up (pwdb de-asserted). Additionally, rstb must be toggled low at least 200 ns after any change in threshold or low-pass filter settings to prevent abnormal trigger events. 0 - Reset glitch detector flags 1 - Glitch detection flags are enabled
  [18:16] VDDR_CORE_GLDTC_CTRL_LP_FILTER_SEL_PROXY — Selects the glitch detect low-pass filter bandwidth Field values (others are reserved): 3'b000 - 150 kHz 3'b001 - 125 kHz 3'b010 - 100 kHz 3'b011 - 80 kHz 3'b100 - 60 kHz 3'b101 - 45 kHz 3'b110 - 30 kHz 3'b111 - 15 kHz
  [13:8] VDDR_CORE_GLDTC_CTRL_THRESH_HI_SEL_PROXY — Selects the high voltage glitch threshold as a percentage of the monitored voltage Field values (others are reserved): 6'b000000 - 93.5% of VDD 6'b000001 - 94.0% of VDD 6'b000010 - 94.5% of VDD 6'b000011 - 95.0% of VDD 6'b000100 - 95.5% of VDD 6'b000101 - 96.0% of VDD 6'b000110 - 96.5% of VDD 6'b000111 - 97.0% of VDD 6'b001000 - 97.5% of VDD 6'b001001 - 98.0% of VDD 6'b001010 - 98.5% of VDD 6'b001011 - 99.0% of VDD 6'b001100 - 99.5% of VDD 6'b001101 - 100.0% of VDD 6'b001110 - 100.5% of VDD 6'b001111 - 101.0% of VDD 6'b010000 - 101.5% of VDD 6'b010001 - 102.0% of VDD 6'b010010 - 102.5% of VDD 6'b010011 - 103.0% of VDD 6'b010100 - 103.5% of VDD 6'b010101 - 104.0% of VDD 6'b010110 - 104.5% of VDD 6'b010111 - 105.0% of VDD 6'b011000 - 105.5% of VDD 6'b011001 - 106.0% of VDD 6'b011010 - 106.5% of VDD 6'b011011 - 107.0% of VDD 6'b011100 - 107.5% of VDD 6'b011101 - 108.0% of VDD 6'b011110 - 108.5% of VDD 6'b011111 - 109.0% of VDD 6'b100000 - 109.5% of VDD 6'b100001 - 110.0% of VDD 6'b100010 - 111.0% of VDD 6'b100011 - 112.0% of VDD 6'b100100 - 113.0% of VDD 6'b100101 - 114.0% of VDD 6'b100110 - 115.0% of VDD 6'b100111 - 116.0% of VDD 6'b101000 - 117.0% of VDD 6'b101001 - 118.0% of VDD 6'b101010 - 119.0% of VDD 6'b101011 - 120.0% of VDD 6'b101100 - 121.0% of VDD 6'b101101 - 122.0% of VDD 6'b101110 - 123.0% of VDD 6'b101111 - 124.0% of VDD 6'b110000 - 125.0% of VDD 6'b110001 - 126.0% of VDD 6'b110010 - 127.0% of VDD 6'b110011 - 128.0% of VDD 6'b110100 - 129.0% of VDD 6'b110101 - 130.0% of VDD 6'b110110 - 131.0% of VDD 6'b110111 - 132.0% of VDD 6'b111000 - 133.0% of VDD 6'b111001 - 134.0% of VDD 6'b111010 - 135.0% of VDD 6'b111011 - 136.0% of VDD 6'b111100 - 137.0% of VDD 6'b111101 - 138.0% of VDD 6'b111110 - 139.0% of VDD 6'b111111 - 140.0% of VDD
  [5:0] VDDR_CORE_GLDTC_CTRL_THRESH_LO_SEL_PROXY — Selects the low voltage glitch threshold as a percentage of the monitored voltage Field values (others are reserved): 6'b000000 - 106.5% of VDD 6'b000001 - 106.0% of VDD 6'b000010 - 105.5% of VDD 6'b000011 - 105.0% of VDD 6'b000100 - 104.5% of VDD 6'b000101 - 104.0% of VDD 6'b000110 - 103.5% of VDD 6'b000111 - 103.0% of VDD 6'b001000 - 102.5% of VDD 6'b001001 - 102.0% of VDD 6'b001010 - 101.5% of VDD 6'b001011 - 101.0% of VDD 6'b001100 - 100.5% of VDD 6'b001101 - 100.0% of VDD 6'b001110 - 99.5% of VDD 6'b001111 - 99.0% of VDD 6'b010000 - 98.5% of VDD 6'b010001 - 98.0% of VDD 6'b010010 - 97.5% of VDD 6'b010011 - 97.0% of VDD 6'b010100 - 96.5% of VDD 6'b010101 - 96.0% of VDD 6'b010110 - 95.5% of VDD 6'b010111 - 95.0% of VDD 6'b011000 - 94.5% of VDD 6'b011001 - 94.0% of VDD 6'b011010 - 93.5% of VDD 6'b011011 - 93.0% of VDD 6'b011100 - 92.5% of VDD 6'b011101 - 92.0% of VDD 6'b011110 - 91.5% of VDD 6'b011111 - 91.0% of VDD 6'b100000 - 90.5% of VDD 6'b100001 - 90.0% of VDD 6'b100010 - 89.0% of VDD 6'b100011 - 88.0% of VDD 6'b100100 - 87.0% of VDD 6'b100101 - 86.0% of VDD 6'b100110 - 85.0% of VDD 6'b100111 - 84.0% of VDD 6'b101000 - 83.0% of VDD 6'b101001 - 82.0% of VDD 6'b101010 - 81.0% of VDD 6'b101011 - 80.0% of VDD 6'b101100 - 79.0% of VDD 6'b101101 - 78.0% of VDD 6'b101110 - 77.0% of VDD 6'b101111 - 76.0% of VDD 6'b110000 - 75.0% of VDD 6'b110001 - 74.0% of VDD 6'b110010 - 73.0% of VDD 6'b110011 - 72.0% of VDD 6'b110100 - 71.0% of VDD 6'b110101 - 70.0% of VDD 6'b110110 - 69.0% of VDD 6'b110111 - 68.0% of VDD 6'b111000 - 67.0% of VDD 6'b111001 - 66.0% of VDD 6'b111010 - 65.0% of VDD 6'b111011 - 64.0% of VDD 6'b111100 - 63.0% of VDD 6'b111101 - 62.0% of VDD 6'b111110 - 61.0% of VDD 6'b111111 - 60.0% of VDD
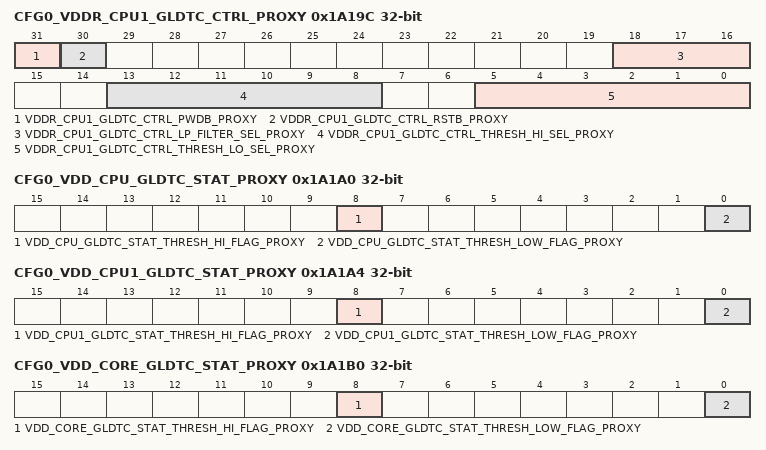
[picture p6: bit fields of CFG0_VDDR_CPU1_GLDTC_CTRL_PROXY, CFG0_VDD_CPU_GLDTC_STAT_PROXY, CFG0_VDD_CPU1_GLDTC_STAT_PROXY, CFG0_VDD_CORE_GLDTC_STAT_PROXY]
0x1A19C CFG0_VDDR_CPU1_GLDTC_CTRL_PROXY
  [31] VDDR_CPU1_GLDTC_CTRL_PWDB_PROXY — Power down - active low. 0 - Disable all functions 1 - Enable glitch detectors
  [30] VDDR_CPU1_GLDTC_CTRL_RSTB_PROXY — Reset - active low. To ensure proper operation, rstb must be not be de-asserted for at least 100 ns after power-up (pwdb de-asserted). Additionally, rstb must be toggled low at least 200 ns after any change in threshold or low-pass filter settings to prevent abnormal trigger events. 0 - Reset glitch detector flags 1 - Glitch detection flags are enabled
  [18:16] VDDR_CPU1_GLDTC_CTRL_LP_FILTER_SEL_PROXY — Selects the glitch detect low-pass filter bandwidth Field values (others are reserved): 3'b000 - 150 kHz 3'b001 - 125 kHz 3'b010 - 100 kHz 3'b011 - 80 kHz 3'b100 - 60 kHz 3'b101 - 45 kHz 3'b110 - 30 kHz 3'b111 - 15 kHz
  [13:8] VDDR_CPU1_GLDTC_CTRL_THRESH_HI_SEL_PROXY — Selects the high voltage glitch threshold as a percentage of the monitored voltage Field values (others are reserved): 6'b000000 - 93.5% of VDD 6'b000001 - 94.0% of VDD 6'b000010 - 94.5% of VDD 6'b000011 - 95.0% of VDD 6'b000100 - 95.5% of VDD 6'b000101 - 96.0% of VDD 6'b000110 - 96.5% of VDD 6'b000111 - 97.0% of VDD 6'b001000 - 97.5% of VDD 6'b001001 - 98.0% of VDD 6'b001010 - 98.5% of VDD 6'b001011 - 99.0% of VDD 6'b001100 - 99.5% of VDD 6'b001101 - 100.0% of VDD 6'b001110 - 100.5% of VDD 6'b001111 - 101.0% of VDD 6'b010000 - 101.5% of VDD 6'b010001 - 102.0% of VDD 6'b010010 - 102.5% of VDD 6'b010011 - 103.0% of VDD 6'b010100 - 103.5% of VDD 6'b010101 - 104.0% of VDD 6'b010110 - 104.5% of VDD 6'b010111 - 105.0% of VDD 6'b011000 - 105.5% of VDD 6'b011001 - 106.0% of VDD 6'b011010 - 106.5% of VDD 6'b011011 - 107.0% of VDD 6'b011100 - 107.5% of VDD 6'b011101 - 108.0% of VDD 6'b011110 - 108.5% of VDD 6'b011111 - 109.0% of VDD 6'b100000 - 109.5% of VDD 6'b100001 - 110.0% of VDD 6'b100010 - 111.0% of VDD 6'b100011 - 112.0% of VDD 6'b100100 - 113.0% of VDD 6'b100101 - 114.0% of VDD 6'b100110 - 115.0% of VDD 6'b100111 - 116.0% of VDD 6'b101000 - 117.0% of VDD 6'b101001 - 118.0% of VDD 6'b101010 - 119.0% of VDD 6'b101011 - 120.0% of VDD 6'b101100 - 121.0% of VDD 6'b101101 - 122.0% of VDD 6'b101110 - 123.0% of VDD 6'b101111 - 124.0% of VDD 6'b110000 - 125.0% of VDD 6'b110001 - 126.0% of VDD 6'b110010 - 127.0% of VDD 6'b110011 - 128.0% of VDD 6'b110100 - 129.0% of VDD 6'b110101 - 130.0% of VDD 6'b110110 - 131.0% of VDD 6'b110111 - 132.0% of VDD 6'b111000 - 133.0% of VDD 6'b111001 - 134.0% of VDD 6'b111010 - 135.0% of VDD 6'b111011 - 136.0% of VDD 6'b111100 - 137.0% of VDD 6'b111101 - 138.0% of VDD 6'b111110 - 139.0% of VDD 6'b111111 - 140.0% of VDD
  [5:0] VDDR_CPU1_GLDTC_CTRL_THRESH_LO_SEL_PROXY — Selects the low voltage glitch threshold as a percentage of the monitored voltage Field values (others are reserved): 6'b000000 - 106.5% of VDD 6'b000001 - 106.0% of VDD 6'b000010 - 105.5% of VDD 6'b000011 - 105.0% of VDD 6'b000100 - 104.5% of VDD 6'b000101 - 104.0% of VDD 6'b000110 - 103.5% of VDD 6'b000111 - 103.0% of VDD 6'b001000 - 102.5% of VDD 6'b001001 - 102.0% of VDD 6'b001010 - 101.5% of VDD 6'b001011 - 101.0% of VDD 6'b001100 - 100.5% of VDD 6'b001101 - 100.0% of VDD 6'b001110 - 99.5% of VDD 6'b001111 - 99.0% of VDD 6'b010000 - 98.5% of VDD 6'b010001 - 98.0% of VDD 6'b010010 - 97.5% of VDD 6'b010011 - 97.0% of VDD 6'b010100 - 96.5% of VDD 6'b010101 - 96.0% of VDD 6'b010110 - 95.5% of VDD 6'b010111 - 95.0% of VDD 6'b011000 - 94.5% of VDD 6'b011001 - 94.0% of VDD 6'b011010 - 93.5% of VDD 6'b011011 - 93.0% of VDD 6'b011100 - 92.5% of VDD 6'b011101 - 92.0% of VDD 6'b011110 - 91.5% of VDD 6'b011111 - 91.0% of VDD 6'b100000 - 90.5% of VDD 6'b100001 - 90.0% of VDD 6'b100010 - 89.0% of VDD 6'b100011 - 88.0% of VDD 6'b100100 - 87.0% of VDD 6'b100101 - 86.0% of VDD 6'b100110 - 85.0% of VDD 6'b100111 - 84.0% of VDD 6'b101000 - 83.0% of VDD 6'b101001 - 82.0% of VDD 6'b101010 - 81.0% of VDD 6'b101011 - 80.0% of VDD 6'b101100 - 79.0% of VDD 6'b101101 - 78.0% of VDD 6'b101110 - 77.0% of VDD 6'b101111 - 76.0% of VDD 6'b110000 - 75.0% of VDD 6'b110001 - 74.0% of VDD 6'b110010 - 73.0% of VDD 6'b110011 - 72.0% of VDD 6'b110100 - 71.0% of VDD 6'b110101 - 70.0% of VDD 6'b110110 - 69.0% of VDD 6'b110111 - 68.0% of VDD 6'b111000 - 67.0% of VDD 6'b111001 - 66.0% of VDD 6'b111010 - 65.0% of VDD 6'b111011 - 64.0% of VDD 6'b111100 - 63.0% of VDD 6'b111101 - 62.0% of VDD 6'b111110 - 61.0% of VDD 6'b111111 - 60.0% of VDD
0x1A1A0 CFG0_VDD_CPU_GLDTC_STAT_PROXY ro
  [8] VDD_CPU_GLDTC_STAT_THRESH_HI_FLAG_PROXY — High voltage flag. This flag is cleared by clearing the VDD_CPU_GLDTC_CTRL_rstb bit. 0 - No high voltage detected 1 - Voltage above the high voltage threshold was detected.
  [0] VDD_CPU_GLDTC_STAT_THRESH_LOW_FLAG_PROXY — Low voltage flag. This flag is cleared by clearing the VDD_CPU_GLDTC_CTRL_rstb bit. 0 - No low voltage detected 1 - Voltage below the low voltage threshold was detected.
0x1A1A4 CFG0_VDD_CPU1_GLDTC_STAT_PROXY ro
  [8] VDD_CPU1_GLDTC_STAT_THRESH_HI_FLAG_PROXY — High voltage flag. This flag is cleared by clearing the VDD_CPU1_GLDTC_CTRL_rstb bit. 0 - No high voltage detected 1 - Voltage above the high voltage threshold was detected.
  [0] VDD_CPU1_GLDTC_STAT_THRESH_LOW_FLAG_PROXY — Low voltage flag. This flag is cleared by clearing the VDD_CPU1_GLDTC_CTRL_rstb bit. 0 - No low voltage detected 1 - Voltage below the low voltage threshold was detected.
0x1A1B0 CFG0_VDD_CORE_GLDTC_STAT_PROXY ro
  [8] VDD_CORE_GLDTC_STAT_THRESH_HI_FLAG_PROXY — High voltage flag. This flag is cleared by clearing the VDD_CORE_GLDTC_CTRL_rstb bit. 0 - No high voltage detected 1 - Voltage above the high voltage threshold was detected.
  [0] VDD_CORE_GLDTC_STAT_THRESH_LOW_FLAG_PROXY — Low voltage flag. This flag is cleared by clearing the VDD_CORE_GLDTC_CTRL_rstb bit. 0 - No low voltage detected 1 - Voltage below the low voltage threshold was detected.
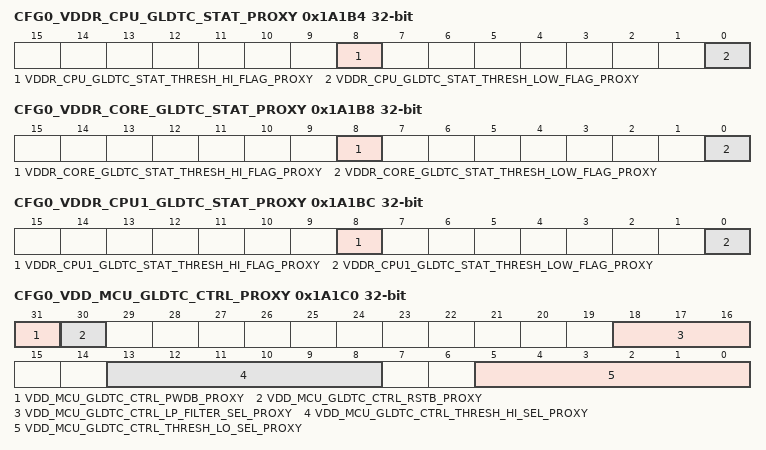
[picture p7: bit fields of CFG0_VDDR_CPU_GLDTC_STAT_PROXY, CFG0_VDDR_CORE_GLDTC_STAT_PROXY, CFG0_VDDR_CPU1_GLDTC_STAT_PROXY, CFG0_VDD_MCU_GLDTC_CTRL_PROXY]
0x1A1B4 CFG0_VDDR_CPU_GLDTC_STAT_PROXY ro
  [8] VDDR_CPU_GLDTC_STAT_THRESH_HI_FLAG_PROXY — High voltage flag. This flag is cleared by clearing the VDDR_CPU_GLDTC_CTRL_rstb bit. 0 - No high voltage detected 1 - Voltage above the high voltage threshold was detected.
  [0] VDDR_CPU_GLDTC_STAT_THRESH_LOW_FLAG_PROXY — Low voltage flag. This flag is cleared by clearing the VDDR_CPU_GLDTC_CTRL_rstb bit. 0 - No low voltage detected 1 - Voltage below the low voltage threshold was detected.
0x1A1B8 CFG0_VDDR_CORE_GLDTC_STAT_PROXY ro
  [8] VDDR_CORE_GLDTC_STAT_THRESH_HI_FLAG_PROXY — High voltage flag. This flag is cleared by clearing the VDDR_CORE_GLDTC_CTRL_rstb bit. 0 - No high voltage detected 1 - Voltage above the high voltage threshold was detected.
  [0] VDDR_CORE_GLDTC_STAT_THRESH_LOW_FLAG_PROXY — Low voltage flag. This flag is cleared by clearing the VDDR_CORE_GLDTC_CTRL_rstb bit. 0 - No low voltage detected 1 - Voltage below the low voltage threshold was detected.
0x1A1BC CFG0_VDDR_CPU1_GLDTC_STAT_PROXY ro
  [8] VDDR_CPU1_GLDTC_STAT_THRESH_HI_FLAG_PROXY — High voltage flag. This flag is cleared by clearing the VDDR_CPU1_GLDTC_CTRL_rstb bit. 0 - No high voltage detected 1 - Voltage above the high voltage threshold was detected.
  [0] VDDR_CPU1_GLDTC_STAT_THRESH_LOW_FLAG_PROXY — Low voltage flag. This flag is cleared by clearing the VDDR_CPU1_GLDTC_CTRL_rstb bit. 0 - No low voltage detected 1 - Voltage below the low voltage threshold was detected.
0x1A1C0 CFG0_VDD_MCU_GLDTC_CTRL_PROXY
  [31] VDD_MCU_GLDTC_CTRL_PWDB_PROXY — Power down - active low. 0 - Disable all functions 1 - Enable glitch detectors
  [30] VDD_MCU_GLDTC_CTRL_RSTB_PROXY — Reset - active low. To ensure proper operation, rstb must be not be de-asserted for at least 100 ns after power-up (pwdb de-asserted). Additionally, rstb must be toggled low at least 200 ns after any change in threshold or low-pass filter settings to prevent abnormal trigger events. 0 - Reset glitch detector flags 1 - Glitch detection flags are enabled
  [18:16] VDD_MCU_GLDTC_CTRL_LP_FILTER_SEL_PROXY — Selects the glitch detect low-pass filter bandwidth Field values (others are reserved): 3'b000 - 150 kHz 3'b001 - 125 kHz 3'b010 - 100 kHz 3'b011 - 80 kHz 3'b100 - 60 kHz 3'b101 - 45 kHz 3'b110 - 30 kHz 3'b111 - 15 kHz
  [13:8] VDD_MCU_GLDTC_CTRL_THRESH_HI_SEL_PROXY — Selects the high voltage glitch threshold as a percentage of the monitored voltage Field values (others are reserved): 6'b000000 - 93.5% of VDD 6'b000001 - 94.0% of VDD 6'b000010 - 94.5% of VDD 6'b000011 - 95.0% of VDD 6'b000100 - 95.5% of VDD 6'b000101 - 96.0% of VDD 6'b000110 - 96.5% of VDD 6'b000111 - 97.0% of VDD 6'b001000 - 97.5% of VDD 6'b001001 - 98.0% of VDD 6'b001010 - 98.5% of VDD 6'b001011 - 99.0% of VDD 6'b001100 - 99.5% of VDD 6'b001101 - 100.0% of VDD 6'b001110 - 100.5% of VDD 6'b001111 - 101.0% of VDD 6'b010000 - 101.5% of VDD 6'b010001 - 102.0% of VDD 6'b010010 - 102.5% of VDD 6'b010011 - 103.0% of VDD 6'b010100 - 103.5% of VDD 6'b010101 - 104.0% of VDD 6'b010110 - 104.5% of VDD 6'b010111 - 105.0% of VDD 6'b011000 - 105.5% of VDD 6'b011001 - 106.0% of VDD 6'b011010 - 106.5% of VDD 6'b011011 - 107.0% of VDD 6'b011100 - 107.5% of VDD 6'b011101 - 108.0% of VDD 6'b011110 - 108.5% of VDD 6'b011111 - 109.0% of VDD 6'b100000 - 109.5% of VDD 6'b100001 - 110.0% of VDD 6'b100010 - 111.0% of VDD 6'b100011 - 112.0% of VDD 6'b100100 - 113.0% of VDD 6'b100101 - 114.0% of VDD 6'b100110 - 115.0% of VDD 6'b100111 - 116.0% of VDD 6'b101000 - 117.0% of VDD 6'b101001 - 118.0% of VDD 6'b101010 - 119.0% of VDD 6'b101011 - 120.0% of VDD 6'b101100 - 121.0% of VDD 6'b101101 - 122.0% of VDD 6'b101110 - 123.0% of VDD 6'b101111 - 124.0% of VDD 6'b110000 - 125.0% of VDD 6'b110001 - 126.0% of VDD 6'b110010 - 127.0% of VDD 6'b110011 - 128.0% of VDD 6'b110100 - 129.0% of VDD 6'b110101 - 130.0% of VDD 6'b110110 - 131.0% of VDD 6'b110111 - 132.0% of VDD 6'b111000 - 133.0% of VDD 6'b111001 - 134.0% of VDD 6'b111010 - 135.0% of VDD 6'b111011 - 136.0% of VDD 6'b111100 - 137.0% of VDD 6'b111101 - 138.0% of VDD 6'b111110 - 139.0% of VDD 6'b111111 - 140.0% of VDD
  [5:0] VDD_MCU_GLDTC_CTRL_THRESH_LO_SEL_PROXY — Selects the low voltage glitch threshold as a percentage of the monitored voltage Field values (others are reserved): 6'b000000 - 106.5% of VDD 6'b000001 - 106.0% of VDD 6'b000010 - 105.5% of VDD 6'b000011 - 105.0% of VDD 6'b000100 - 104.5% of VDD 6'b000101 - 104.0% of VDD 6'b000110 - 103.5% of VDD 6'b000111 - 103.0% of VDD 6'b001000 - 102.5% of VDD 6'b001001 - 102.0% of VDD 6'b001010 - 101.5% of VDD 6'b001011 - 101.0% of VDD 6'b001100 - 100.5% of VDD 6'b001101 - 100.0% of VDD 6'b001110 - 99.5% of VDD 6'b001111 - 99.0% of VDD 6'b010000 - 98.5% of VDD 6'b010001 - 98.0% of VDD 6'b010010 - 97.5% of VDD 6'b010011 - 97.0% of VDD 6'b010100 - 96.5% of VDD 6'b010101 - 96.0% of VDD 6'b010110 - 95.5% of VDD 6'b010111 - 95.0% of VDD 6'b011000 - 94.5% of VDD 6'b011001 - 94.0% of VDD 6'b011010 - 93.5% of VDD 6'b011011 - 93.0% of VDD 6'b011100 - 92.5% of VDD 6'b011101 - 92.0% of VDD 6'b011110 - 91.5% of VDD 6'b011111 - 91.0% of VDD 6'b100000 - 90.5% of VDD 6'b100001 - 90.0% of VDD 6'b100010 - 89.0% of VDD 6'b100011 - 88.0% of VDD 6'b100100 - 87.0% of VDD 6'b100101 - 86.0% of VDD 6'b100110 - 85.0% of VDD 6'b100111 - 84.0% of VDD 6'b101000 - 83.0% of VDD 6'b101001 - 82.0% of VDD 6'b101010 - 81.0% of VDD 6'b101011 - 80.0% of VDD 6'b101100 - 79.0% of VDD 6'b101101 - 78.0% of VDD 6'b101110 - 77.0% of VDD 6'b101111 - 76.0% of VDD 6'b110000 - 75.0% of VDD 6'b110001 - 74.0% of VDD 6'b110010 - 73.0% of VDD 6'b110011 - 72.0% of VDD 6'b110100 - 71.0% of VDD 6'b110101 - 70.0% of VDD 6'b110110 - 69.0% of VDD 6'b110111 - 68.0% of VDD 6'b111000 - 67.0% of VDD 6'b111001 - 66.0% of VDD 6'b111010 - 65.0% of VDD 6'b111011 - 64.0% of VDD 6'b111100 - 63.0% of VDD 6'b111101 - 62.0% of VDD 6'b111110 - 61.0% of VDD 6'b111111 - 60.0% of VDD
